# ATSAMA5D35 device description
Architecture: CORTEX-A5; Family: SAMA5
Registers are 32-bit, read-write, no defined reset value unless marked. A register's access mark holds for its fields unless they carry their own. Offsets are from the block's base; [hi:lo] are bit positions; {n}, {i} and the like mark numbered series; 'fields as' and 'values as' point back to an identical list.

## GMAC — Gigabit Ethernet MAC
Instances: GMAC 0xF0028000
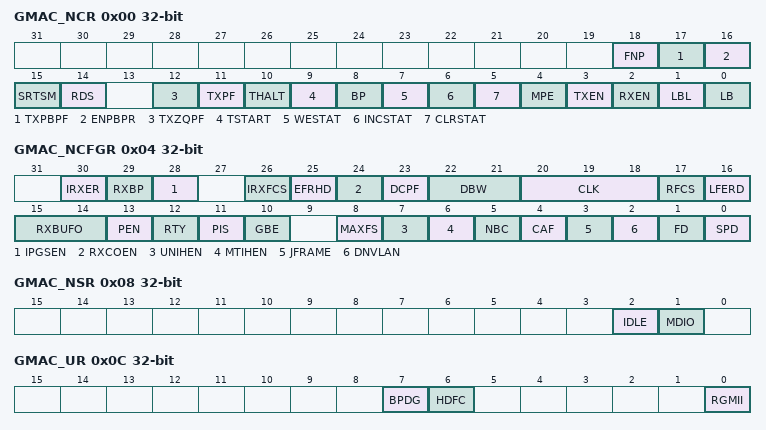
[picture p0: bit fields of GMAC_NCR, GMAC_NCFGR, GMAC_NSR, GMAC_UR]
0x00 GMAC_NCR — Network Control Register
  [18] FNP — Flush Next Packet
  [17] TXPBPF — Transmit PFC Priority-based Pause Frame
  [16] ENPBPR — Enable PFC Priority-based Pause Reception
  [15] SRTSM — Store Receive Time Stamp to Memory
  [14] RDS — Read Snapshot
  [12] TXZQPF — Transmit Zero Quantum Pause Frame
  [11] TXPF — Transmit Pause Frame
  [10] THALT — Transmit Halt
  [9] TSTART — Start Transmission
  [8] BP — Back pressure
  [7] WESTAT — Write Enable for Statistics Registers
  [6] INCSTAT — Increment Statistics Registers
  [5] CLRSTAT — Clear Statistics Registers
  [4] MPE — Management Port Enable
  [3] TXEN — Transmit Enable
  [2] RXEN — Receive Enable
  [1] LBL — Loop Back Local
  [0] LB — Loop Back
0x04 GMAC_NCFGR — Network Configuration Register
  [30] IRXER — Ignore IPG rx_er
  [29] RXBP — Receive Bad Preamble
  [28] IPGSEN — IP Stretch Enable
  [26] IRXFCS — Ignore RX FCS
  [25] EFRHD — Enable Frames Received in Half Duplex
  [24] RXCOEN — Receive Checksum Offload Enable
  [23] DCPF — Disable Copy of Pause Frames
  [22:21] DBW — Data Bus Width
    0=32-bit data bus width; 1=64-bit data bus width
  [20:18] CLK — MDC CLock Division
    0=MCK_8 (MCK divided by 8 (MCK up to 20 MHz)); 1=MCK_16 (MCK divided by 16 (MCK up to 40 MHz)); 2=MCK_32 (MCK divided by 32 (MCK up to 80 MHz)); 3=MCK_48 (MCK divided by 48 (MCK up to 120MHz)); 4=MCK_64 (MCK divided by 64 (MCK up to 160 MHz)); 5=MCK_96 (MCK divided by 96 (MCK up to 240 MHz)); 6=MCK_128 (MCK divided by 128 (MCK up to 320 MHz)); 7=MCK_224 (MCK divided by 224 (MCK up to 540 MHz))
  [17] RFCS — Remove FCS
  [16] LFERD — Length Field Error Frame Discard
  [15:14] RXBUFO — Receive Buffer Offset
  [13] PEN — Pause Enable
  [12] RTY — Retry Test
  [11] PIS — Physical Interface Select
  [10] GBE — Gigabit Mode Enable
  [8] MAXFS — 1536 Maximum Frame Size
  [7] UNIHEN — Unicast Hash Enable
  [6] MTIHEN — Multicast Hash Enable
  [5] NBC — No Broadcast
  [4] CAF — Copy All Frames
  [3] JFRAME — Jumbo Frame Size
  [2] DNVLAN — Discard Non-VLAN FRAMES
  [1] FD — Full Duplex
  [0] SPD — Speed
0x08 GMAC_NSR ro — Network Status Register
  [2] IDLE — PHY Management Logic Idle
  [1] MDIO — MDIO Input Status
0x0C GMAC_UR — User Register
  [7] BPDG — BPDG Bypass Deglitchers
  [6] HDFC — Half Duplex Flow Control
  [0] RGMII — RGMII Mode
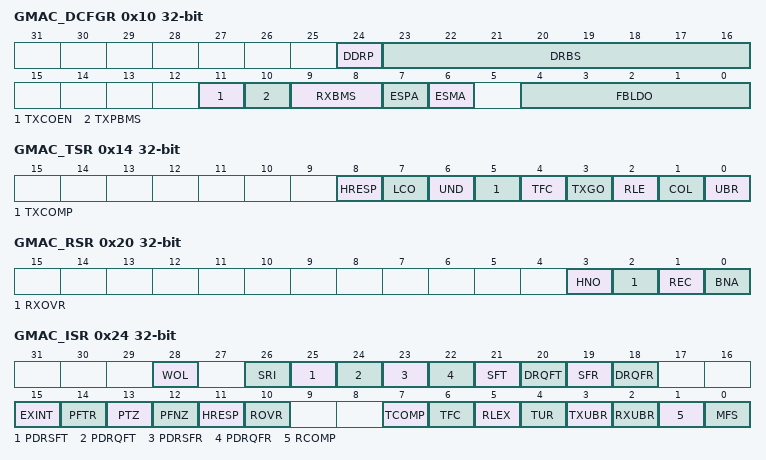
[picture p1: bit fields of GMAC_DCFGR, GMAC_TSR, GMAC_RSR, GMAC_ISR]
0x10 GMAC_DCFGR — DMA Configuration Register
  [24] DDRP — DMA Discard Receive Packets
  [23:16] DRBS — DMA Receive Buffer Size
  [11] TXCOEN — Transmitter Checksum Generation Offload Enable
  [10] TXPBMS — Transmitter Packet Buffer Memory Size Select
  [9:8] RXBMS — Receiver Packet Buffer Memory Size Select
    0=EIGHTH (1 Kbyte Memory Size); 1=QUARTER (2 Kbytes Memory Size); 2=HALF (4 Kbytes Memory Size); 3=FULL (8 Kbytes Memory Size)
  [7] ESPA — Endian Swap Mode Enable for Packet Data Accesses
  [6] ESMA — Endian Swap Mode Enable for Management Descriptor Accesses
  [4:0] FBLDO — Fixed Burst Length for DMA Data Operations:
    1=SINGLE (00001: Always use SINGLE AHB bursts); 4=INCR4 (001xx: Attempt to use INCR4 AHB bursts (Default)); 8=INCR8 (01xxx: Attempt to use INCR8 AHB bursts); 16=INCR16 (1xxxx: Attempt to use INCR16 AHB bursts)
0x14 GMAC_TSR — Transmit Status Register
  [8] HRESP — HRESP Not OK
  [7] LCO — Late Collision Occurred
  [6] UND — Transmit Under Run
  [5] TXCOMP — Transmit Complete
  [4] TFC — Transmit Frame Corruption due to AHB error
  [3] TXGO — Transmit Go
  [2] RLE — Retry Limit Exceeded
  [1] COL — Collision Occurred
  [0] UBR — Used Bit Read
0x18 GMAC_RBQB — Receive Buffer Queue Base Address
  [31:2] ADDR — Receive buffer queue base address
0x1C GMAC_TBQB — Transmit Buffer Queue Base Address
  [31:2] ADDR
0x20 GMAC_RSR — Receive Status Register
  [3] HNO — HRESP Not OK
  [2] RXOVR — Receive Overrun
  [1] REC — Frame Received
  [0] BNA — Buffer Not Available
0x24 GMAC_ISR ro — Interrupt Status Register
  [28] WOL — Wake On LAN
  [26] SRI — TSU Seconds Register Increment
  [25] PDRSFT — PDelay Response Frame Transmitted
  [24] PDRQFT — PDelay Request Frame Transmitted
  [23] PDRSFR — PDelay Response Frame Received
  [22] PDRQFR — PDelay Request Frame Received
  [21] SFT — PTP Sync Frame Transmitted
  [20] DRQFT — PTP Delay Request Frame Transmitted
  [19] SFR — PTP Sync Frame Received
  [18] DRQFR — PTP Delay Request Frame Received
  [15] EXINT — External Interrupt
  [14] PFTR — Pause Frame Transmitted
  [13] PTZ — Pause Time Zero
  [12] PFNZ — Pause Frame with Non-zero Pause Quantum Received
  [11] HRESP — HRESP Not OK
  [10] ROVR — Receive Overrun
  [7] TCOMP — Transmit Complete
  [6] TFC — Transmit Frame Corruption due to AHB error
  [5] RLEX — Retry Limit Exceeded or Late Collision
  [4] TUR — Transmit Under Run
  [3] TXUBR — TX Used Bit Read
  [2] RXUBR — RX Used Bit Read
  [1] RCOMP — Receive Complete
  [0] MFS — Management Frame Sent
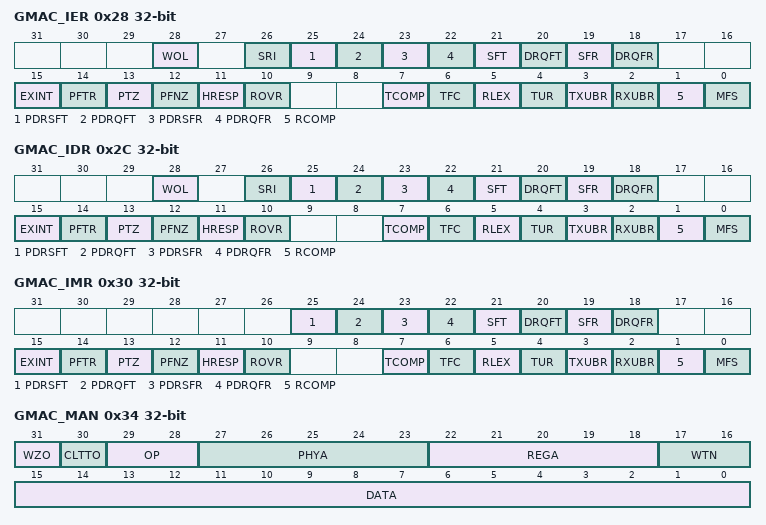
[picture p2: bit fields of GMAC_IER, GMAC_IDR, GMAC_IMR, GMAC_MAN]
0x28 GMAC_IER wo — Interrupt Enable Register
  fields as GMAC_ISR
0x2C GMAC_IDR wo — Interrupt Disable Register
  fields as GMAC_ISR
0x30 GMAC_IMR ro — Interrupt Mask Register
  [25] PDRSFT — PDelay Response Frame Transmitted
  [24] PDRQFT — PDelay Request Frame Transmitted
  [23] PDRSFR — PDelay Response Frame Received
  [22] PDRQFR — PDelay Request Frame Received
  [21] SFT — PTP Sync Frame Transmitted
  [20] DRQFT — PTP Delay Request Frame Transmitted
  [19] SFR — PTP Sync Frame Received
  [18] DRQFR — PTP Delay Request Frame Received
  [15] EXINT — External Interrupt
  [14] PFTR — Pause Frame Transmitted
  [13] PTZ — Pause Time Zero
  [12] PFNZ — Pause Frame with Non-zero Pause Quantum Received
  [11] HRESP — HRESP Not OK
  [10] ROVR — Receive Overrun
  [7] TCOMP — Transmit Complete
  [6] TFC — Transmit Frame Corruption due to AHB error
  [5] RLEX — Retry Limit Exceeded or Late Collision
  [4] TUR — Transmit Under Run
  [3] TXUBR — TX Used Bit Read
  [2] RXUBR — RX Used Bit Read
  [1] RCOMP — Receive Complete
  [0] MFS — Management Frame Sent
0x34 GMAC_MAN — PHY Maintenance Register
  [31] WZO — Write ZERO
  [30] CLTTO — Clause 22 Operation
  [29:28] OP — Operation
  [27:23] PHYA — PHY Address
  [22:18] REGA — Register Address
  [17:16] WTN — Write Ten
  [15:0] DATA — PHY Data
0x38 GMAC_RPQ ro — Received Pause Quantum Register
  [15:0] RPQ — Received Pause Quantum
0x3C GMAC_TPQ — Transmit Pause Quantum Register
  [15:0] TPQ — Transmit Pause Quantum
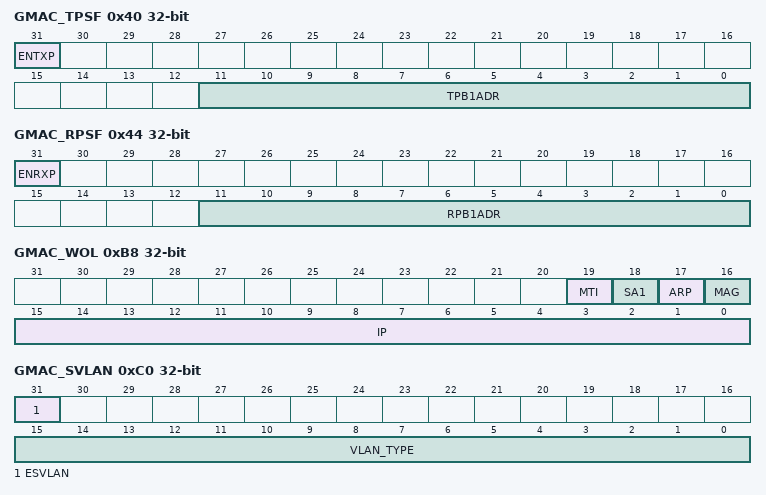
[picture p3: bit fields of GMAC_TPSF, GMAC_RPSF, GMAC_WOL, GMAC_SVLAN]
0x40 GMAC_TPSF — TX Partial Store and Forward Register
  [31] ENTXP — Enable TX Partial Store and Forward Operation
  [11:0] TPB1ADR — tx_pbuf_addr-1:0
0x44 GMAC_RPSF — RX Partial Store and Forward Register
  [31] ENRXP — Enable RX Partial Store and Forward Operation
  [11:0] RPB1ADR — rx_pbuf_addr-1:0
0x80 GMAC_HRB — Hash Register Bottom [31:0]
  [31:0] ADDR — Hash Address
0x84 GMAC_HRT — Hash Register Top [63:32]
  [31:0] ADDR — Hash Address
{0x80+8i} GMAC_SAB{i} (i=1..4) — Specific Address {i} Bottom [31:0] Register
  [31:0] ADDR — Specific Address {i}
{0x84+8i} GMAC_SAT{i} (i=1..4) — Specific Address {i} Top [47:32] Register
  [15:0] ADDR — Specific Address {i}
{0xA8+4i} GMAC_TIDM{i} (i=0..3) — Type ID Match 1 Register {i}
  [15:0] TID — Type ID Match 1
0xB8 GMAC_WOL — Wake on LAN Register
  [19] MTI — Multicast Hash Event Enable
  [18] SA1 — Specific Address Register 1 Event Enable
  [17] ARP — ARP Request IP Address
  [16] MAG — Magic Packet Event Enable
  [15:0] IP — ARP Request IP Address
0xBC GMAC_IPGS — IPG Stretch Register
  [15:0] FL — Frame Length
0xC0 GMAC_SVLAN — Stacked VLAN Register
  [31] ESVLAN — Enable Stacked VLAN Processing Mode
  [15:0] VLAN_TYPE — User Defined VLAN_TYPE Field
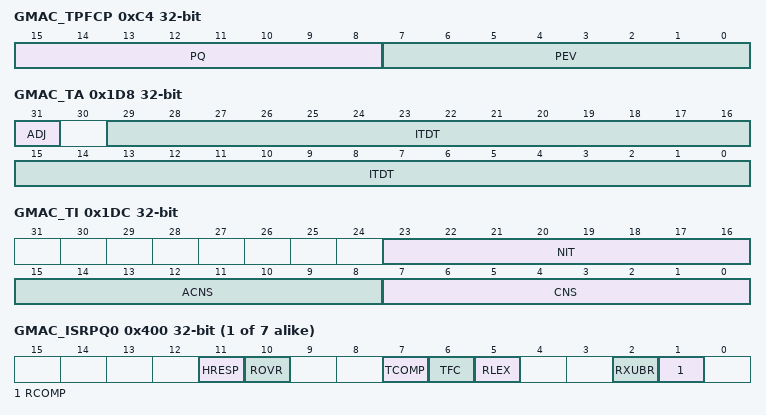
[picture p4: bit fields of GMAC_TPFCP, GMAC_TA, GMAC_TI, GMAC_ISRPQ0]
0xC4 GMAC_TPFCP — Transmit PFC Pause Register
  [15:8] PQ — Pause Quantum
  [7:0] PEV — Priority Enable Vector
0xC8 GMAC_SAMB1 — Specific Address 1 Mask Bottom [31:0] Register
  [31:0] ADDR — Specific Address 1 Mask
0xCC GMAC_SAMT1 — Specific Address 1 Mask Top [47:32] Register
  [15:0] ADDR — Specific Address 1 Mask
0x100 GMAC_OTLO ro — Octets Transmitted [31:0] Register
  [31:0] TXO — Transmitted Octets
0x104 GMAC_OTHI ro — Octets Transmitted [47:32] Register
  [15:0] TXO — Transmitted Octets
0x108 GMAC_FT ro — Frames Transmitted Register
  [31:0] FTX — Frames Transmitted without Error
0x10C GMAC_BCFT ro — Broadcast Frames Transmitted Register
  [31:0] BFTX — Broadcast Frames Transmitted without Error
0x110 GMAC_MFT ro — Multicast Frames Transmitted Register
  [31:0] MFTX — Multicast Frames Transmitted without Error
0x114 GMAC_PFT ro — Pause Frames Transmitted Register
  [15:0] PFTX
0x118 GMAC_BFT64 ro — 64 Byte Frames Transmitted Register
  [31:0] NFTX — 64 Byte Frames Transmitted without Error
0x11C GMAC_TBFT127 ro — 65 to 127 Byte Frames Transmitted Register
  [31:0] NFTX — 65 to 127 Byte Frames Transmitted without Error
0x120 GMAC_TBFT255 ro — 128 to 255 Byte Frames Transmitted Register
  [31:0] NFTX — 128 to 255 Byte Frames Transmitted without Error
0x124 GMAC_TBFT511 ro — 256 to 511 Byte Frames Transmitted Register
  [31:0] NFTX — 256 to 511 Byte Frames Transmitted without Error
0x128 GMAC_TBFT1023 ro — 512 to 1023 Byte Frames Transmitted Register
  [31:0] NFTX — 512 to 1023 Byte Frames Transmitted without Error
0x12C GMAC_TBFT1518 ro — 1024 to 1518 Byte Frames Transmitted Register
  [31:0] NFTX — 1024 to 1518 Byte Frames Transmitted without Error
0x130 GMAC_GTBFT1518 ro — Greater Than 1518 Byte Frames Transmitted Register
  [31:0] NFTX — Greater than 1518 Byte Frames Transmitted without Error
0x134 GMAC_TUR ro — Transmit Under Runs Register
  [9:0] TXUNR — Transmit Under Runs
0x138 GMAC_SCF ro — Single Collision Frames Register
  [17:0] SCOL — Single Collision
0x13C GMAC_MCF ro — Multiple Collision Frames Register
  [17:0] MCOL — Multiple Collision
0x140 GMAC_EC ro — Excessive Collisions Register
  [9:0] XCOL — Excessive Collisions
0x144 GMAC_LC ro — Late Collisions Register
  [9:0] LCOL — Late Collisions
0x148 GMAC_DTF ro — Deferred Transmission Frames Register
  [17:0] DEFT — Deferred Transmission
0x14C GMAC_CSE ro — Carrier Sense Errors Register
  [9:0] CSR — Carrier Sense Error
0x150 GMAC_ORLO ro — Octets Received [31:0] Received
  [31:0] RXO — Received Octets
0x154 GMAC_ORHI ro — Octets Received [47:32] Received
  [15:0] RXO — Received Octets
0x158 GMAC_FR ro — Frames Received Register
  [31:0] FRX — Frames Received without Error
0x15C GMAC_BCFR ro — Broadcast Frames Received Register
  [31:0] BFRX — Broadcast Frames Received without Error
0x160 GMAC_MFR ro — Multicast Frames Received Register
  [31:0] MFRX — Multicast Frames Received without Error
0x164 GMAC_PFR ro — Pause Frames Received Register
  [15:0] PFRX
0x168 GMAC_BFR64 ro — 64 Byte Frames Received Register
  [31:0] NFRX — 64 Byte Frames Received without Error
0x16C GMAC_TBFR127 ro — 65 to 127 Byte Frames Received Register
  [31:0] NFRX — 65 to 127 Byte Frames Received without Error
0x170 GMAC_TBFR255 ro — 128 to 255 Byte Frames Received Register
  [31:0] NFRX — 128 to 255 Byte Frames Received without Error
0x174 GMAC_TBFR511 ro — 256 to 511Byte Frames Received Register
  [31:0] NFRX — 256 to 511 Byte Frames Received without Error
0x178 GMAC_TBFR1023 ro — 512 to 1023 Byte Frames Received Register
  [31:0] NFRX — 512 to 1023 Byte Frames Received without Error
0x17C GMAC_TBFR1518 ro — 1024 to 1518 Byte Frames Received Register
  [31:0] NFRX — 1024 to 1518 Byte Frames Received without Error
0x180 GMAC_TMXBFR ro — 1519 to Maximum Byte Frames Received Register
  [31:0] NFRX — 1519 to Maximum Byte Frames Received without Error
0x184 GMAC_UFR ro — Undersize Frames Received Register
  [9:0] UFRX — Undersize Frames Received
0x188 GMAC_OFR ro — Oversize Frames Received Register
  [9:0] OFRX — Oversized Frames Received
0x18C GMAC_JR ro — Jabbers Received Register
  [9:0] JRX — Jabbers Received
0x190 GMAC_FCSE ro — Frame Check Sequence Errors Register
  [9:0] FCKR — Frame Check Sequence Errors
0x194 GMAC_LFFE ro — Length Field Frame Errors Register
  [9:0] LFER — Length Field Frame Errors
0x198 GMAC_RSE ro — Receive Symbol Errors Register
  [9:0] RXSE — Receive Symbol Errors
0x19C GMAC_AE ro — Alignment Errors Register
  [9:0] AER — Alignment Errors
0x1A0 GMAC_RRE ro — Receive Resource Errors Register
  [17:0] RXRER — Receive Resource Errors
0x1A4 GMAC_ROE ro — Receive Overrun Register
  [9:0] RXOVR — Receive Overruns
0x1A8 GMAC_IHCE ro — IP Header Checksum Errors Register
  [7:0] HCKER — IP Header Checksum Errors
0x1AC GMAC_TCE ro — TCP Checksum Errors Register
  [7:0] TCKER — TCP Checksum Errors
0x1B0 GMAC_UCE ro — UDP Checksum Errors Register
  [7:0] UCKER — UDP Checksum Errors
0x1C8 GMAC_TSSS — 1588 Timer Sync Strobe Seconds Register
  [31:0] VTS — Value of Timer Seconds Register Capture
0x1CC GMAC_TSSN — 1588 Timer Sync Strobe Nanoseconds Register
  [29:0] VTN — Value Timer Nanoseconds Register Capture
0x1D0 GMAC_TS — 1588 Timer Seconds Register
  [31:0] TCS — Timer Count in Seconds
0x1D4 GMAC_TN — 1588 Timer Nanoseconds Register
  [29:0] TNS — Timer Count in Nanoseconds
0x1D8 GMAC_TA wo — 1588 Timer Adjust Register
  [31] ADJ — Adjust 1588 Timer
  [29:0] ITDT — Increment/Decrement
0x1DC GMAC_TI — 1588 Timer Increment Register
  [23:16] NIT — Number of Increments
  [15:8] ACNS — Alternative Count Nanoseconds
  [7:0] CNS — Count Nanoseconds
0x1E0 GMAC_EFTS ro — PTP Event Frame Transmitted Seconds
  [31:0] RUD — Register Update
0x1E4 GMAC_EFTN ro — PTP Event Frame Transmitted Nanoseconds
  [29:0] RUD — Register Update
0x1E8 GMAC_EFRS ro — PTP Event Frame Received Seconds
  [31:0] RUD — Register Update
0x1EC GMAC_EFRN ro — PTP Event Frame Received Nanoseconds
  [29:0] RUD — Register Update
0x1F0 GMAC_PEFTS ro — PTP Peer Event Frame Transmitted Seconds
  [31:0] RUD — Register Update
0x1F4 GMAC_PEFTN ro — PTP Peer Event Frame Transmitted Nanoseconds
  [29:0] RUD — Register Update
0x1F8 GMAC_PEFRS ro — PTP Peer Event Frame Received Seconds
  [31:0] RUD — Register Update
0x1FC GMAC_PEFRN ro — PTP Peer Event Frame Received Nanoseconds
  [29:0] RUD — Register Update
{0x400+4i} GMAC_ISRPQ{i} ro (i=0..6) — Interrupt Status Register Priority Queue {i}
  [11] HRESP — HRESP Not OK
  [10] ROVR — Receive Overrun
  [7] TCOMP — Transmit Complete
  [6] TFC — Transmit Frame Corruption due to AHB error
  [5] RLEX — Retry Limit Exceeded or Late Collision
  [2] RXUBR — RX Used Bit Read
  [1] RCOMP — Receive Complete
{0x440+4i} GMAC_TBQBAPQ{i} (i=0..6) — Transmit Buffer Queue Base Address Priority Queue {i}
  [7:2] TXBQBA — Transmit Buffer Queue Base Address
{0x480+4i} GMAC_RBQBAPQ{i} (i=0..6) — Receive Buffer Queue Base Address Priority Queue {i}
  [7:2] RXBQBA — Receive Buffer Queue Base Address
{0x4A0+4i} GMAC_RBSRPQ{i} (i=0..6) — Receive Buffer Size Register Priority Queue {i}
  [15:0] RBS — Receive Buffer Size
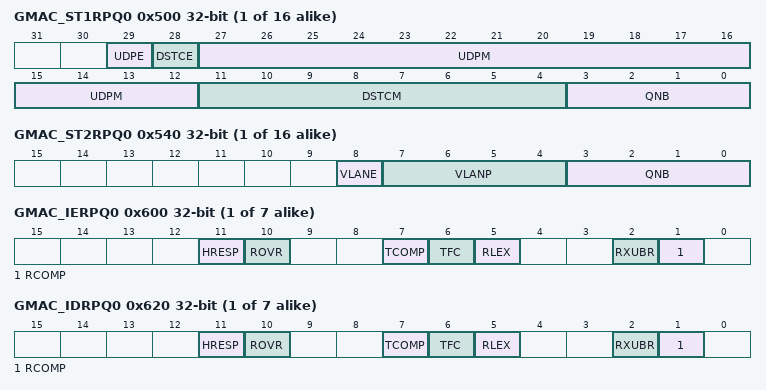
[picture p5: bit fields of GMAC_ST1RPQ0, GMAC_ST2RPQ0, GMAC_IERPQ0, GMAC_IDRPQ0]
{0x500+4i} GMAC_ST1RPQ{i} (i=0..15) — Screening Type1 Register Priority Queue {i}
  [29] UDPE — UDP Port Match Enable
  [28] DSTCE — Differentiated Services or Traffic Class Match Enable
  [27:12] UDPM — UDP Port Match
  [11:4] DSTCM — Differentiated Services or Traffic Class Match
  [3:0] QNB — Que Number (0->7)
{0x540+4i} GMAC_ST2RPQ{i} (i=0..15) — Screening Type2 Register Priority Queue {i}
  [8] VLANE — VLAN Enable
  [7:4] VLANP — VLAN Priority
  [3:0] QNB — Que Number (0->7)
{0x600+4i} GMAC_IERPQ{i} wo (i=0..6) — Interrupt Enable Register Priority Queue {i}
  fields as GMAC_ISRPQ0
{0x620+4i} GMAC_IDRPQ{i} wo (i=0..6) — Interrupt Disable Register Priority Queue {i}
  fields as GMAC_ISRPQ0
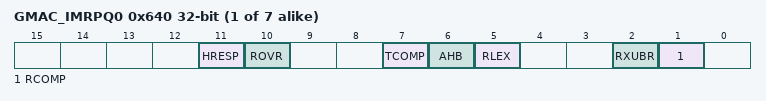
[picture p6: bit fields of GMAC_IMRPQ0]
{0x640+4i} GMAC_IMRPQ{i} (i=0..6) — Interrupt Mask Register Priority Queue {i}
  [11] HRESP — HRESP Not OK
  [10] ROVR — Receive Overrun
  [7] TCOMP — Transmit Complete
  [6] AHB — AHB Error
  [5] RLEX — Retry Limit Exceeded or Late Collision
  [2] RXUBR — RX Used Bit Read
  [1] RCOMP — Receive Complete
